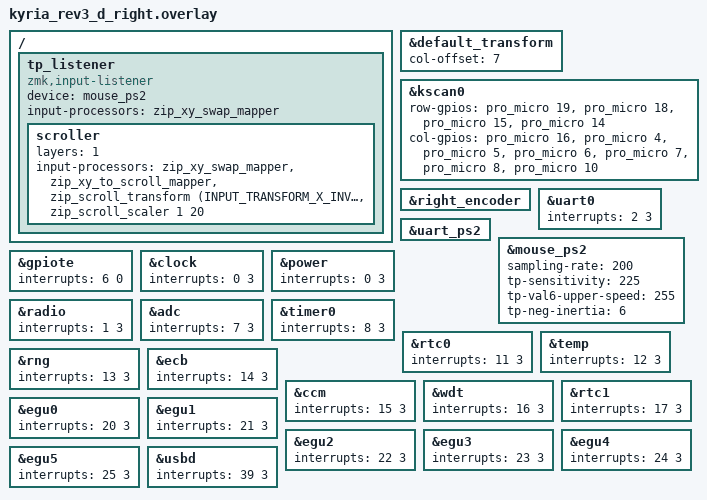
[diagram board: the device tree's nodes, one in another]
/*
 * Copyright (c) 2023 The ZMK Contributors
 *
 * SPDX-License-Identifier: MIT
 */

#include "kyria_rev3_d.dtsi"
#include <input/processors.dtsi>
#include <dt-bindings/zmk/input_transform.h>

&default_transform {
    col-offset = <7>;
};

&kscan0 {
    row-gpios
    = <&pro_micro 19 (GPIO_ACTIVE_HIGH | GPIO_PULL_DOWN)>
    , <&pro_micro 18 (GPIO_ACTIVE_HIGH | GPIO_PULL_DOWN)>
    , <&pro_micro 15 (GPIO_ACTIVE_HIGH | GPIO_PULL_DOWN)>
    , <&pro_micro 14 (GPIO_ACTIVE_HIGH | GPIO_PULL_DOWN)>
    ;
    col-gpios
    = <&pro_micro 16 GPIO_ACTIVE_HIGH>
    , <&pro_micro 4  GPIO_ACTIVE_HIGH>
    , <&pro_micro 5  GPIO_ACTIVE_HIGH>
    , <&pro_micro 6  GPIO_ACTIVE_HIGH>
    , <&pro_micro 7  GPIO_ACTIVE_HIGH>
    , <&pro_micro 8  GPIO_ACTIVE_HIGH>
    , <&pro_micro 10 GPIO_ACTIVE_HIGH>
    ;
};

// Plain EC11 for this encoder, accepting occasional missed detents on the
// busy central: a hardware-QDEC variant decoded perfectly but coincided
// with degraded trackpoint feel, and the trackpoint wins. (See git history
// for the QDEC setup if encoders ever become a priority.)
&right_encoder {
    status = "okay";
};

/*
 * PS/2 Mouse / Trackpoint (lives on this half; right is the split central)
 */

&uart0 {
    status = "okay";
};

&uart_ps2 {
    status = "okay";
};

&mouse_ps2 {
    status = "okay";

    sampling-rate = <200>;

    // See TP documentation at https://blogs.epfl.ch/icenet/documents/Ykt3Eext.pdf
    // pages 24, 43 and 44 explain the following settings
    tp-sensitivity = <225>;
    tp-val6-upper-speed = <255>;
    tp-neg-inertia = <6>;
};

/ {
    tp_listener: tp_listener {
        compatible = "zmk,input-listener";
        device = <&mouse_ps2>;

        // The trackpoint is mounted rotated; swap X/Y in the listener
        // (this trackpoint doesn't support tp-xy-swap in &mouse_ps2).
        input-processors = <&zip_xy_swap_mapper>;

        // Trackpoint scrolls while the SYM layer is held.
        // Replaces the old scroll-layers + scroll-accelerator setup:
        // swap axes, map XY to wheel/hwheel, reverse horizontal direction,
        // then scale down 1:20 (the old accelerator used divisor = <20>).
        scroller {
            layers = <1>;
            input-processors = <&zip_xy_swap_mapper>,
                               <&zip_xy_to_scroll_mapper>,
                               <&zip_scroll_transform (INPUT_TRANSFORM_X_INVERT)>,
                               <&zip_scroll_scaler 1 20>;
        };
    };
};

// Interrupt priorities for the PS/2 driver (per its Kconfig docs):
// PS/2 events must be processed within 30-50us, so GPIOTE gets the highest
// priority (0) and the driver's Kconfig shifts the BT controller down to
// 1/2 (CONFIG_BT_CTLR_LLL_PRIO/ULL_*). Everything else that is actually
// enabled in this build gets demoted to 3 so it cannot contend with BT.
// (The original infused-kim example demoted ~40 peripherals; overrides on
// disabled peripherals are no-ops, so only the live ones are kept here.)

&gpiote {
    interrupts = < 6 0 >;
};

&clock {
    interrupts = < 0 3 >;
};

&power {
    interrupts = < 0 3 >;
};

&radio {
    interrupts = < 1 3 >;
};

// PS/2 RX itself; above the rest but below gpiote
&uart0 {
    interrupts = < 2 3 >;
};

&adc {
    interrupts = < 7 3 >;
};

&timer0 {
    interrupts = < 8 3 >;
};

&rtc0 {
    interrupts = < 11 3 >;
};

&temp {
    interrupts = < 12 3 >;
};

&rng {
    interrupts = < 13 3 >;
};

&ecb {
    interrupts = < 14 3 >;
};

&ccm {
    interrupts = < 15 3 >;
};

&wdt {
    interrupts = < 16 3 >;
};

&rtc1 {
    interrupts = < 17 3 >;
};

&egu0 {
    interrupts = < 20 3 >;
};

&egu1 {
    interrupts = < 21 3 >;
};

&egu2 {
    interrupts = < 22 3 >;
};

&egu3 {
    interrupts = < 23 3 >;
};

&egu4 {
    interrupts = < 24 3 >;
};

&egu5 {
    interrupts = < 25 3 >;
};

&usbd {
    interrupts = < 39 3 >;
};
